# PIC32MZ1025W104132 device description
Architecture: MIPS; Family: PIC32MZW; Series: PIC32MZW
Registers are 32-bit, read-write, no defined reset value unless marked. A register's access mark holds for its fields unless they carry their own. Offsets are from the block's base; [hi:lo] are bit positions; {n}, {i} and the like mark numbered series; 'fields as' and 'values as' point back to an identical list.

## PPS
Instances: PPS 0x1f801800 in periph_pb1a
{0x0+4i} INT{i}R (i=0..4)
  [3:0] INT{i}R
{0x10+4i} T{i}CKR (i=1..7)
  [3:0] T{i}CKR
{0x34+4i} IC{i}R (i=1..4)
  [3:0] IC{i}R
0x5C OCFAR
  [3:0] OCFAR
0x60 OCFBR
  [3:0] OCFBR
0x64 OCFCR
  [3:0] OCFCR
0x68 OCFDR
  [3:0] OCFDR
{0x64+8i} U{i}RXR (i=1..3)
  [3:0] U{i}RXR
{0x68+8i} U{i}CTSR (i=1..3)
  [3:0] U{i}CTSR
0x8C PTG30R
  [3:0] PTG30R
0x90 PTG31R
  [3:0] PTG31R
0x98 SDI1R
  [3:0] SDI1R
0x9C SS1INR
  [3:0] SS1INR
0xA4 SDI2R
  [3:0] SDI2R
0xA8 SS2INR
  [3:0] SS2INR
0xC4 C1RXR
  [3:0] C1RXR
0xC8 C2RXR
  [3:0] C2RXR
0xCC REFIR
  [3:0] REFIR
0x174 ECOLR
  [3:0] ECOLR
0x178 ECRSR
  [3:0] ECRSR
0x17C ETXCLKR
  [3:0] ETXCLKR
0x180 ERXD3R
  [3:0] ERXD3R
0x184 ERXD2R
  [3:0] ERXD2R
{0x200+4i} RPA{i}R (i=0..5)
  [3:0] RPA{i}R
{0x200+4i} RPA{i}R (i=10..15)
  [3:0] RPA{i}R
{0x240+4i} RPB{i}R (i=0..14)
  [3:0] RPB{i}R
{0x280+4i} RPC{i}R (i=0..15)
  [3:0] RPC{i}R
{0x2C0+4i} RPK{i}R (i=0..14)
  [3:0] RPK{i}R

## PTG
Instances: PTG 0x1f801c00 in periph_pb1a
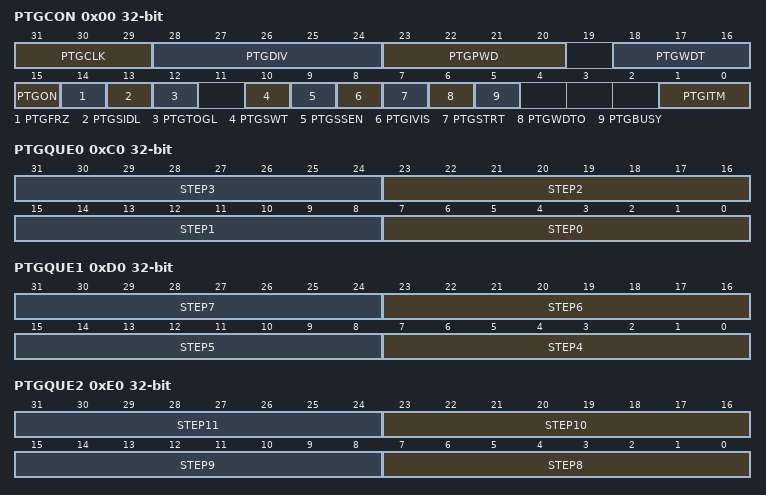
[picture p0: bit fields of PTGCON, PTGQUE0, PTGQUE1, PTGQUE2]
0x00 PTGCON
  [31:29] PTGCLK, [28:24] PTGDIV, [23:20] PTGPWD, [18:16] PTGWDT, [15] PTGON, [14] PTGFRZ, [13] PTGSIDL, [12] PTGTOGL, [10] PTGSWT, [9] PTGSSEN, [8] PTGIVIS, [7] PTGSTRT, [6] PTGWDTO, [5] PTGBUSY, [1:0] PTGITM
0x10 PTGBTE
0x20 PTGHOLD
  [15:0] PTGHOLD
0x30 PTGT0LIM
  [15:0] PTGT0LIM
0x40 PTGT1LIM
  [15:0] PTGT1LIM
0x50 PTGSDLIM
  [15:0] PTGSDLIM
0x60 PTGC0LIM
  [15:0] PTGC0LIM
0x70 PTGC1LIM
  [15:0] PTGC1LIM
0x80 PTGADJ
  [15:0] PTGADJ
0x90 PTGL0
  [15:0] PTGL0
0xA0 PTGQPTR
  [4:0] PTGQPTR
0xC0 PTGQUE0
  [8n+7:8n] STEP{n} (n=0..3)
0xD0 PTGQUE1
  [8n-25:8n-32] STEP{n} (n=4..7)
0xE0 PTGQUE2
  [8n-57:8n-64] STEP{n} (n=8..11)
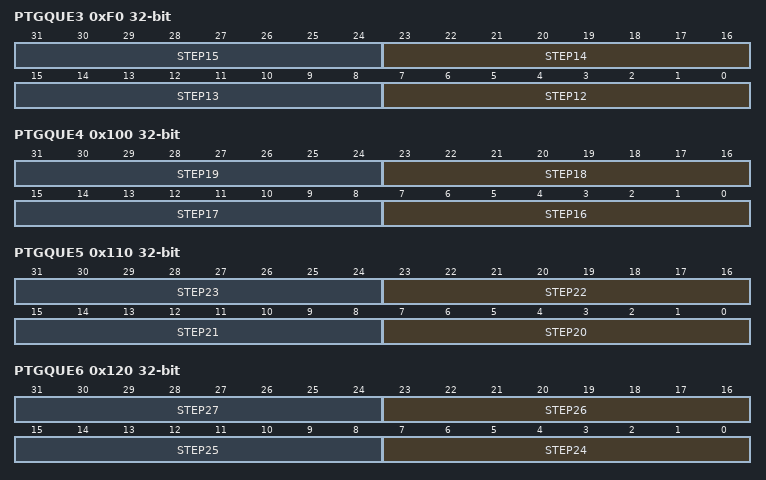
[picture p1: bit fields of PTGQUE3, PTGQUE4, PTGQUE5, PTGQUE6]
0xF0 PTGQUE3
  [8n-89:8n-96] STEP{n} (n=12..15)
0x100 PTGQUE4
  [8n-121:8n-128] STEP{n} (n=16..19)
0x110 PTGQUE5
  [8n-153:8n-160] STEP{n} (n=20..23)
0x120 PTGQUE6
  [8n-185:8n-192] STEP{n} (n=24..27)
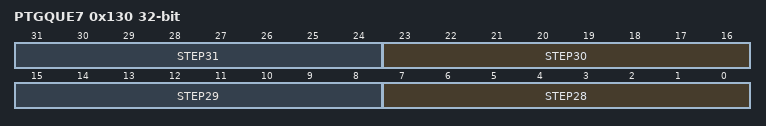
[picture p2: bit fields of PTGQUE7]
0x130 PTGQUE7
  [8n-217:8n-224] STEP{n} (n=28..31)

## RNG
Instances: RNG 0x1f8e5000 in periph_indep_a
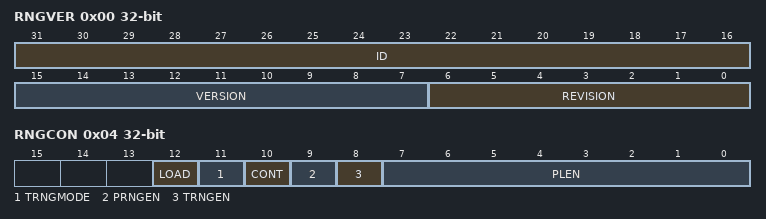
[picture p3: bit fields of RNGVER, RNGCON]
0x00 RNGVER ro — Random Number Generator Version Register
  [31:16] ID, [15:7] VERSION, [6:0] REVISION
0x04 RNGCON — Random Number Generator Control Register
  [12] LOAD
  [11] TRNGMODE — TRNG Mode Selection bit
    1=Use ring oscillators with bias corrector; 0=Use ring oscillators with XOR tree
  [10] CONT — PRNG Number Shift Enable bit
    1=The PRNG random number is shifted every cycle; 0=The PRNG random number is shifted when the previous value is removed
  [9] PRNGEN — PRNG Operation Enable bit
    1=PRNG operation is enabled; 0=PRNG operation is not enabled
  [8] TRNGEN — TRNG Operation Enable bit
    1=TRNG operation is enabled; 0=TRNG operation is not enabled
  [7:0] PLEN
0x08 RNGPOLY1 — Random Number Generator Polynomial Register 1
  [31:0] POLY
0x0C RNGPOLY2 — Random Number Generator Polynomial Register 2
  [31:0] POLY
0x10 RNGNUMGEN1 — Random Number Generator Register 1
  [31:0] RNG
0x14 RNGNUMGEN2 — Random Number Generator Register 2
  [31:0] RNG
0x18 RNGSEED1 ro — True Random Number Generator Seed Register 1
  [31:0] SEED
0x1C RNGSEED2 ro — True Random Number Generator Seed Register 2
  [31:0] SEED
0x20 RNGCNT — True Random Number Generator Count Register
  [6:0] RCNT

## TMR1
Instances: TMR1 0x1f802000 in periph_pb1a
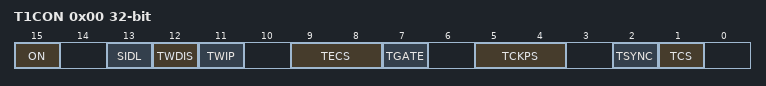
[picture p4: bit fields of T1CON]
0x00 T1CON — TYPE A TIMER CONTROL REGISTER
  [15] ON — Timer On bit
    1=Timer is enabled; 0=Timer is disabled
  [13] SIDL — Stop in Idle Mode bit
    1=Discontinue operation when device enters Idle mode; 0=Continue operation even in Idle mode
  [12] TWDIS — Asynchronous Timer Write Disable bit
    1=Writes to TMR1 are ignored until pending write operation completes; 0=Back-to-back writes are enabled (Legacy Asynchronous Timer functionality)
  [11] TWIP — Asynchronous Timer Write in Progress bit
    1=(In Asynchronous Timer mode) Asynchronous write to TMR1 register in progress / (In Synchronous Timer mode)bit is read as 0; 0=In Asynchronous Timer mode Asynchronous write to TMR1 register complete / (In Synchronous Timer mode)bit is read as 0
  [9:8] TECS — Timer1 External Clock Selection bits
    2=External clock comes from the LPRC; 1=External clock comes from the T1CK pin; 0=External clock comes from the SOSC
  [7] TGATE — Timer Gated Time Accumulation Enable bit
    1=(When TCS is 0) Gated time accumulation is enabled / (When TCS is 1) bit is ignored; 0=(When TCS is 0) Gated time accumulation is disabled / (When TCS is 1) bit is ignored
  [5:4] TCKPS — Timer Input Clock Prescale Select bits
    3=1:256 prescale value; 2=1:64 prescale value; 1=1:8 prescale value; 0=1:1 prescale value
  [2] TSYNC — Timer External Clock Input Synchronization Selection bit
    1=(When TCS is 1) External clock input is synchronized / (When TCS is 0) This bit is ignored; 0=(When TCS is 1) External clock input is not synchronized / (When TCS is 0) This bit is ignored
  [1] TCS — Timer Clock Source Select bit
    1=External clock is defined by the TECS bits; 0=Internal peripheral clock
0x10 TMR1
0x20 PR1

## TMR
Instances: TMR 0x1f802200 in periph_pb1a
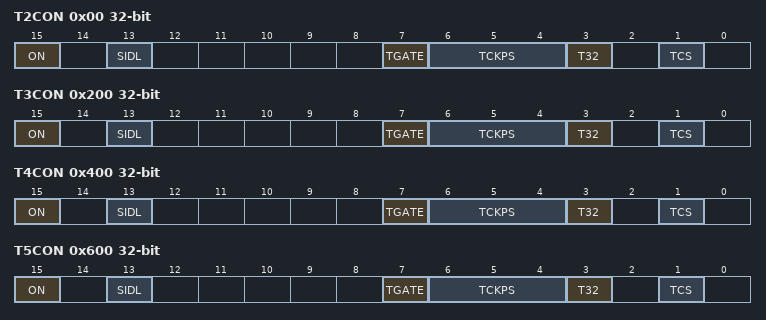
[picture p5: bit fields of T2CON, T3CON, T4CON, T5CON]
0x00 T2CON — Type B Timer Control Register
  [15] ON — Timer On bit
    1=Module is enabled; 0=Module is disabled
  [13] SIDL — Stop in Idle Mode bit
    1=Discontinue operation when device enters Idle mode; 0=Continue operation even in Idle mode
  [7] TGATE — Timer Gated Time Accumulation Enable bit
    1=(When TCS is 1): This bit is ignored and is read as 0 / (When TCS=0): Gated time accumulation is enabled; 0=(When TCS is 1): This bit is ignored and is read as 0 / (When TCS=0): Gated time accumulation is disabled
  [6:4] TCKPS — Timer Input Clock Prescale Select bits
    7=1:256 prescale value; 6=1:64 prescale value; 5=1:32 prescale value; 4=1:16 prescale value; 3=1:8 prescale value; 2=1:4 prescale value; 1=1:2 prescale value; 0=1:1 prescale value
  [3] T32 — 32-Bit Timer Mode Select bit
    1=Odd numbered and even numbered timers form a 32-bit timer; 0=Odd numbered and even numbered timers form separate 16-bit timers
  [1] TCS — Timer Clock Source Select bit
    1=External clock from TxCK pin; 0=Internal peripheral clock
0x10 TMR2
0x20 PR2
0x200 T3CON — Type B Timer Control Register
  fields as T2CON
0x210 TMR3
0x220 PR3
0x400 T4CON — Type B Timer Control Register
  fields as T2CON
0x410 TMR4
0x420 PR4
0x600 T5CON — Type B Timer Control Register
  fields as T2CON
0x610 TMR5
0x620 PR5
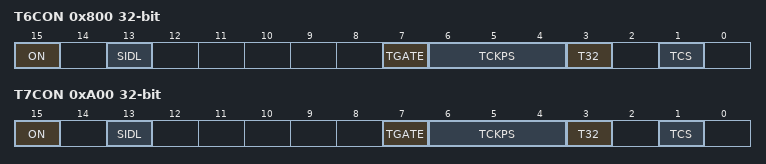
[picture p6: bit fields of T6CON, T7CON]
0x800 T6CON — Type B Timer Control Register
  fields as T2CON
0x810 TMR6
0x820 PR6
0xA00 T7CON — Type B Timer Control Register
  fields as T2CON
0xA10 TMR7
0xA20 PR7

## WDT
Instances: WDT 0x1f800800 in periph_pb1a
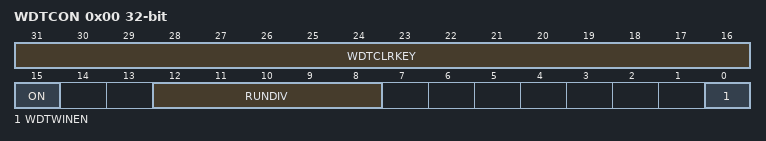
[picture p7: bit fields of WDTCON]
0x00 WDTCON — Watchdog Timer Control Register
  [31:16] WDTCLRKEY
  [15] ON — Watchdog Timer Enable bit
    1=The WDT module is enabled; 0=The WDT module is disabled
  [12:8] RUNDIV
  [0] WDTWINEN — Watchdog Timer Window Enable bit
    1=Enable windowed Watchdog Timer; 0=Disable windowed Watchdog Timer
